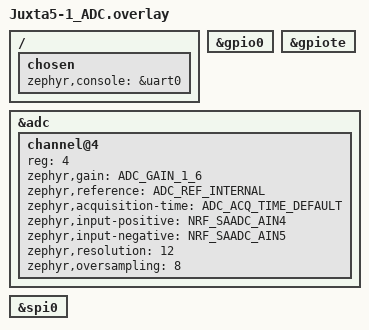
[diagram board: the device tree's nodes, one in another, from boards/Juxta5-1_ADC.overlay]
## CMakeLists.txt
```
#-------------------------------------------------------------------------------
# Zephyr Example Application
#
# Copyright (c) 2021 Nordic Semiconductor ASA
# SPDX-License-Identifier: Apache-2.0

cmake_minimum_required(VERSION 3.13.1)
find_package(Zephyr REQUIRED HINTS $ENV{ZEPHYR_BASE})

project(app LANGUAGES C)

target_sources(app PRIVATE 
    src/simple_main.c
    src/juxta5_example.c
)
```

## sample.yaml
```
# This file is provided so that the application can be compiled using Twister,
# the Zephyr testing tool. In this file, multiple combinations can be specified,
# so that you can easily test all of them locally or in CI.
sample:
  description: Example application
  name: example-application
common:
  sysbuild: true
  build_only: true
  integration_platforms:
    - custom_plank
    - Juxta5-1_ADC
tests:
  app.default: {}
  app.debug:
    extra_overlay_confs:
      - debug.conf
```

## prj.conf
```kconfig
# Copyright (c) 2021 Nordic Semiconductor ASA
# SPDX-License-Identifier: Apache-2.0
#
# This file contains selected Kconfig options for the application.

# Enable GPIO for magnet sensor interrupt
CONFIG_GPIO=y

# Enable SPI for FRAM
CONFIG_SPI=y
CONFIG_SPI_NRFX=y

# Enable ADC for differential measurement
CONFIG_ADC=y
CONFIG_ADC_NRFX_SAADC=y

# Enable EEPROM support for FRAM (use standard driver)
CONFIG_EEPROM=y
CONFIG_EEPROM_AT25=y

# Enable logging
CONFIG_LOG=y
CONFIG_LOG_DEFAULT_LEVEL=3

# Enable RTT for logging (since no UART available)
CONFIG_USE_SEGGER_RTT=y
CONFIG_CONSOLE=y
CONFIG_RTT_CONSOLE=y
CONFIG_SEGGER_RTT_MODE_NO_BLOCK_SKIP=y
# Disable UART console (since no UART available)
CONFIG_UART_CONSOLE=n

# Original example application drivers (for custom drivers in common/)
# CONFIG_SENSOR=y  # Disabled for board-specific testing
```

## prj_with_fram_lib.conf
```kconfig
# Copyright (c) 2021 Nordic Semiconductor ASA
# SPDX-License-Identifier: Apache-2.0
#
# Configuration file demonstrating FRAM library usage

# Enable GPIO for magnet sensor interrupt
CONFIG_GPIO=y

# Enable SPI for FRAM
CONFIG_SPI=y
CONFIG_SPI_NRFX=y

# Enable ADC for differential measurement
CONFIG_ADC=y
CONFIG_ADC_NRFX_SAADC=y

# Enable JUXTA FRAM Library (NEW!)
CONFIG_JUXTA_FRAM=y
CONFIG_JUXTA_FRAM_LOG_LEVEL_DBG=y

# Enable logging
CONFIG_LOG=y
CONFIG_LOG_DEFAULT_LEVEL=3

# Enable RTT for logging (since no UART available)
CONFIG_USE_SEGGER_RTT=y
CONFIG_CONSOLE=y
CONFIG_RTT_CONSOLE=y
CONFIG_SEGGER_RTT_MODE_NO_BLOCK_SKIP=y
# Disable UART console (since no UART available)
CONFIG_UART_CONSOLE=n

# Note: EEPROM drivers not needed when using FRAM library
# The library handles SPI communication directly
# CONFIG_EEPROM=y
# CONFIG_EEPROM_AT25=y 
```

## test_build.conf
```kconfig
# Minimal test configuration for Juxta5-1_ADC
# This removes potentially problematic drivers

# Basic system
CONFIG_GPIO=y
CONFIG_LOG=y
CONFIG_LOG_DEFAULT_LEVEL=3

# Enable RTT for logging (since no UART available)
CONFIG_USE_SEGGER_RTT=y
CONFIG_RTT_CONSOLE=y

# SPI for FRAM
CONFIG_SPI=y
CONFIG_SPI_NRFX=y

# ADC for differential measurement
CONFIG_ADC=y
CONFIG_ADC_NRFX_SAADC=y

# EEPROM for FRAM
CONFIG_EEPROM=y
CONFIG_EEPROM_AT25=y 
```

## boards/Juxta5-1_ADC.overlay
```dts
/*
 * Board overlay for Juxta5-1_ADC specific configurations
 * This file demonstrates how to use all the board peripherals
 */

/ {
	chosen {
		/* No UART available on this board */
		zephyr,console = &uart0; /* Will be ignored since no UART */
	};
};

/* Configure GPIO for magnet sensor interrupt */
&gpio0 {
	status = "okay";
};

/* Configure GPIOTE for interrupt handling */
&gpiote {
	status = "okay";
};

/* Configure ADC for differential measurement */
&adc {
	status = "okay";
	
	/* ADC channel 4 configured for differential measurement */
	/* P0.04 (negative) and P0.05 (positive) */
	#address-cells = <1>;
	#size-cells = <0>;
	
	channel@4 {
		reg = <4>;
		zephyr,gain = "ADC_GAIN_1_6";
		zephyr,reference = "ADC_REF_INTERNAL";
		zephyr,acquisition-time = <ADC_ACQ_TIME_DEFAULT>;
		zephyr,input-positive = <NRF_SAADC_AIN4>; /* P0.04 */
		zephyr,input-negative = <NRF_SAADC_AIN5>; /* P0.05 */
		zephyr,resolution = <12>;
		zephyr,oversampling = <8>;
	};
};

/* Configure SPI for FRAM */
&spi0 {
	status = "okay";
	
	/* FRAM device is already configured in board DTS */
	/* Access via device tree alias: spi-fram */
}; 
```

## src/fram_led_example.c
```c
/*
 * Example demonstrating shared CS/LED pin usage
 * Shows how to safely switch between FRAM and LED modes
 */

#include <zephyr/kernel.h>
#include <zephyr/device.h>
#include <zephyr/drivers/gpio.h>
#include <zephyr/logging/log.h>
#include <juxta_fram/fram.h>
#include <string.h>

LOG_MODULE_REGISTER(fram_led_example, LOG_LEVEL_DBG);

/* Device tree definitions */
#define LED_NODE DT_ALIAS(led0)
#define FRAM_NODE DT_ALIAS(spi_fram)

/* GPIO specifications */
static const struct gpio_dt_spec led_gpio = GPIO_DT_SPEC_GET(LED_NODE, gpios);

/* FRAM device instance */
static struct juxta_fram_device fram_dev;

/**
 * @brief Demonstrate FRAM operations
 */
static int demo_fram_operations(void)
{
    int ret;

    LOG_INF("=== FRAM Operations Demo ===");

    /* FRAM operations automatically switch to SPI mode */
    uint8_t test_data[] = {0x11, 0x22, 0x33, 0x44};
    uint32_t test_addr = 0x2000;

    ret = juxta_fram_write(&fram_dev, test_addr, test_data, sizeof(test_data));
    if (ret < 0)
    {
        LOG_ERR("FRAM write failed: %d", ret);
        return ret;
    }

    uint8_t read_data[sizeof(test_data)] = {0};
    ret = juxta_fram_read(&fram_dev, test_addr, read_data, sizeof(read_data));
    if (ret < 0)
    {
        LOG_ERR("FRAM read failed: %d", ret);
        return ret;
    }

    /* Verify data */
    bool match = true;
    for (size_t i = 0; i < sizeof(test_data); i++)
    {
        if (test_data[i] != read_data[i])
        {
            match = false;
            break;
        }
    }

    if (match)
    {
        LOG_INF("✅ FRAM read/write successful");
    }
    else
    {
        LOG_ERR("❌ FRAM data mismatch");
        return -1;
    }

    return 0;
}

/**
 * @brief Demonstrate LED operations
 */
static int demo_led_operations(void)
{
    int ret;

    LOG_INF("=== LED Operations Demo ===");

    /* Switch to LED mode */
    ret = juxta_fram_led_mode_enable(&fram_dev);
    if (ret < 0)
    {
        LOG_ERR("Failed to enable LED mode: %d", ret);
        return ret;
    }

    LOG_INF("LED mode enabled - testing LED functions...");

    /* Test individual LED functions */
    LOG_INF("Turning LED ON");
    ret = juxta_fram_led_on(&fram_dev);
    if (ret < 0)
    {
        LOG_ERR("LED on failed: %d", ret);
        return ret;
    }
    k_sleep(K_MSEC(500));

    LOG_INF("Turning LED OFF");
    ret = juxta_fram_led_off(&fram_dev);
    if (ret < 0)
    {
        LOG_ERR("LED off failed: %d", ret);
        return ret;
    }
    k_sleep(K_MSEC(500));

    /* Test toggle function */
    LOG_INF("Toggling LED 5 times...");
    for (int i = 0; i < 5; i++)
    {
        ret = juxta_fram_led_toggle(&fram_dev);
        if (ret < 0)
        {
            LOG_ERR("LED toggle failed: %d", ret);
            return ret;
        }
        k_sleep(K_MSEC(200));
    }

    /* Test set function */
    LOG_INF("Using led_set function...");
    ret = juxta_fram_led_set(&fram_dev, true); /* ON */
    if (ret < 0)
    {
        LOG_ERR("LED set failed: %d", ret);
        return ret;
    }
    k_sleep(K_MSEC(300));

    ret = juxta_fram_led_set(&fram_dev, false); /* OFF */
    if (ret < 0)
    {
        LOG_ERR("LED set failed: %d", ret);
        return ret;
    }

    LOG_INF("✅ LED operations successful");
    return 0;
}

/**
 * @brief Demonstrate mixed FRAM and LED usage
 */
static int demo_mixed_operations(void)
{
    int ret;

    LOG_INF("=== Mixed FRAM/LED Operations Demo ===");

    for (int cycle = 0; cycle < 3; cycle++)
    {
        LOG_INF("--- Cycle %d ---", cycle + 1);

        /* Store cycle count in FRAM */
        uint32_t cycle_addr = 0x3000 + (cycle * 4);
        ret = juxta_fram_write(&fram_dev, cycle_addr, (uint8_t *)&cycle, sizeof(cycle));
        if (ret < 0)
        {
            LOG_ERR("Failed to write cycle to FRAM: %d", ret);
            return ret;
        }
        LOG_INF("Stored cycle %d in FRAM at address 0x%06X", cycle, cycle_addr);

        /* Switch to LED mode and blink */
        ret = juxta_fram_led_mode_enable(&fram_dev);
        if (ret < 0)
        {
            LOG_ERR("Failed to enable LED mode: %d", ret);
            return ret;
        }

        /* Blink LED (cycle + 1) times */
        LOG_INF("Blinking LED %d times", cycle + 1);
        for (int blink = 0; blink < (cycle + 1); blink++)
        {
            juxta_fram_led_on(&fram_dev);
            k_sleep(K_MSEC(200));
            juxta_fram_led_off(&fram_dev);
            k_sleep(K_MSEC(200));
        }

        /* Read back from FRAM (automatically switches to SPI mode) */
        int read_cycle = -1;
        ret = juxta_fram_read(&fram_dev, cycle_addr, (uint8_t *)&read_cycle, sizeof(read_cycle));
        if (ret < 0)
        {
            LOG_ERR("Failed to read cycle from FRAM: %d", ret);
            return ret;
        }

        if (read_cycle == cycle)
        {
            LOG_INF("✅ Cycle %d verified from FRAM", read_cycle);
        }
        else
        {
            LOG_ERR("❌ FRAM verification failed: expected %d, got %d", cycle, read_cycle);
            return -1;
        }

        k_sleep(K_SECONDS(1));
    }

    LOG_INF("✅ Mixed operations successful");
    return 0;
}

/**
 * @brief Demonstrate error handling when using wrong mode
 */
static int demo_error_handling(void)
{
    int ret;

    LOG_INF("=== Error Handling Demo ===");

    /* Try LED operation without enabling LED mode */
    LOG_INF("Attempting LED operation in SPI mode (should fail)...");
    ret = juxta_fram_led_on(&fram_dev);
    if (ret == JUXTA_FRAM_ERROR_MODE)
    {
        LOG_INF("✅ Correctly rejected LED operation in SPI mode");
    }
    else
    {
        LOG_ERR("❌ Should have failed with mode error");
        return -1;
    }

    /* Enable LED mode */
    ret = juxta_fram_led_mode_enable(&fram_dev);
    if (ret < 0)
    {
        LOG_ERR("Failed to enable LED mode: %d", ret);
        return ret;
    }

    /* Now LED operations should work */
    ret = juxta_fram_led_on(&fram_dev);
    if (ret == JUXTA_FRAM_OK)
    {
        LOG_INF("✅ LED operation successful after enabling LED mode");
    }
    else
    {
        LOG_ERR("❌ LED operation failed: %d", ret);
        return ret;
    }

    /* FRAM operation will automatically switch modes */
    LOG_INF("Performing FRAM operation (should auto-switch modes)...");
    uint8_t test_byte = 0x55;
    ret = juxta_fram_write_byte(&fram_dev, 0x4000, test_byte);
    if (ret == JUXTA_FRAM_OK)
    {
        LOG_INF("✅ FRAM operation successful (auto mode switch)");
    }
    else
    {
        LOG_ERR("❌ FRAM operation failed: %d", ret);
        return ret;
    }

    /* Check current mode */
    if (juxta_fram_is_led_mode(&fram_dev))
    {
        LOG_INF("Currently in LED mode");
    }
    else
    {
        LOG_INF("Currently in SPI mode");
    }

    LOG_INF("✅ Error handling demo successful");
    return 0;
}

/**
 * @brief Main demonstration function
 */
int fram_led_example_main(void)
{
    int ret;

    LOG_INF("Starting FRAM/LED Shared Pin Demo");

    /* Initialize FRAM */
    ret = juxta_fram_init_dt(&fram_dev, DEVICE_DT_GET(FRAM_NODE), &led_gpio);
    if (ret < 0)
    {
        LOG_ERR("Failed to initialize FRAM: %d", ret);
        return ret;
    }

    /* Verify FRAM is working */
    ret = juxta_fram_test(&fram_dev, 0x1000);
    if (ret < 0)
    {
        LOG_ERR("FRAM test failed: %d", ret);
        return ret;
    }

    LOG_INF("🎯 FRAM Library initialized successfully");
    LOG_INF("Pin P0.%02d is shared between FRAM CS and LED", led_gpio.pin);

    /* Run demonstration functions */
    ret = demo_fram_operations();
    if (ret < 0)
        return ret;

    k_sleep(K_SECONDS(1));

    ret = demo_led_operations();
    if (ret < 0)
        return ret;

    k_sleep(K_SECONDS(1));

    ret = demo_mixed_operations();
    if (ret < 0)
        return ret;

    k_sleep(K_SECONDS(1));

    ret = demo_error_handling();
    if (ret < 0)
        return ret;

    LOG_INF("🎉 All demonstrations completed successfully!");

    /* Final demonstration: continuous operation */
    LOG_INF("Starting continuous demo (Ctrl+C to stop)...");

    uint32_t counter = 0;
    while (1)
    {
        /* Store counter in FRAM */
        uint32_t addr = 0x5000;
        ret = juxta_fram_write(&fram_dev, addr, (uint8_t *)&counter, sizeof(counter));
        if (ret < 0)
        {
            LOG_ERR("FRAM write failed: %d", ret);
            break;
        }

        /* Switch to LED mode and flash */
        juxta_fram_led_mode_enable(&fram_dev);
        juxta_fram_led_on(&fram_dev);
        k_sleep(K_MSEC(100));
        juxta_fram_led_off(&fram_dev);

        /* Read back from FRAM */
        uint32_t read_counter;
        ret = juxta_fram_read(&fram_dev, addr, (uint8_t *)&read_counter, sizeof(read_counter));
        if (ret < 0)
        {
            LOG_ERR("FRAM read failed: %d", ret);
            break;
        }

        LOG_INF("Counter: %u (FRAM verified)", read_counter);

        counter++;
        k_sleep(K_SECONDS(2));
    }

    return 0;
}
```

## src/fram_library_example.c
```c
/*
 * Example usage of the JUXTA FRAM Library
 * This demonstrates the clean API for FRAM operations
 */

#include <zephyr/kernel.h>
#include <zephyr/device.h>
#include <zephyr/drivers/gpio.h>
#include <zephyr/logging/log.h>
#include <juxta_fram/fram.h>
#include <string.h>

LOG_MODULE_REGISTER(fram_example, LOG_LEVEL_DBG);

/* Device tree definitions */
#define LED_NODE DT_ALIAS(led0)
#define FRAM_NODE DT_ALIAS(spi_fram)

/* GPIO specifications */
static const struct gpio_dt_spec led = GPIO_DT_SPEC_GET(LED_NODE, gpios);

/* FRAM device instance */
static struct juxta_fram_device fram_dev;

/**
 * @brief Example of FRAM library usage
 */
int fram_library_example_main(void)
{
    int ret;

    LOG_INF("Starting FRAM Library Example");

    /* Initialize FRAM using the library */
    ret = juxta_fram_init_dt(&fram_dev, DEVICE_DT_GET(FRAM_NODE), &led);
    if (ret < 0)
    {
        LOG_ERR("Failed to initialize FRAM: %d", ret);
        return ret;
    }

    /* Verify FRAM device ID */
    struct juxta_fram_id id;
    ret = juxta_fram_read_id(&fram_dev, &id);
    if (ret < 0)
    {
        LOG_ERR("Failed to verify FRAM ID: %d", ret);
        return ret;
    }

    LOG_INF("FRAM Device ID verified:");
    LOG_INF("  Manufacturer: 0x%02X", id.manufacturer_id);
    LOG_INF("  Continuation: 0x%02X", id.continuation_code);
    LOG_INF("  Product ID 1: 0x%02X", id.product_id_1);
    LOG_INF("  Product ID 2: 0x%02X", id.product_id_2);

    /* Run built-in test */
    ret = juxta_fram_test(&fram_dev, 0x1000); /* Test at address 0x1000 */
    if (ret < 0)
    {
        LOG_ERR("FRAM test failed: %d", ret);
        return ret;
    }

    /* Example: Write a string to FRAM */
    const char *test_string = "Hello FRAM Library!";
    uint32_t string_addr = 0x2000;

    ret = juxta_fram_write(&fram_dev, string_addr,
                           (const uint8_t *)test_string,
                           strlen(test_string) + 1); /* +1 for null terminator */
    if (ret < 0)
    {
        LOG_ERR("Failed to write string to FRAM: %d", ret);
        return ret;
    }

    LOG_INF("Wrote string to FRAM at address 0x%06X", string_addr);

    /* Example: Read the string back */
    char read_buffer[64] = {0};
    ret = juxta_fram_read(&fram_dev, string_addr,
                          (uint8_t *)read_buffer,
                          strlen(test_string) + 1);
    if (ret < 0)
    {
        LOG_ERR("Failed to read string from FRAM: %d", ret);
        return ret;
    }

    LOG_INF("Read string from FRAM: '%s'", read_buffer);

    /* Verify the data matches */
    if (strcmp(test_string, read_buffer) == 0)
    {
        LOG_INF("✅ String read/write test passed!");
    }
    else
    {
        LOG_ERR("❌ String read/write test failed!");
        return -1;
    }

    /* Example: Write and read individual bytes */
    uint32_t data_addr = 0x3000;
    uint8_t test_data[] = {0xAA, 0x55, 0xFF, 0x00, 0x12, 0x34, 0x56, 0x78};
    uint8_t read_data[sizeof(test_data)] = {0};

    ret = juxta_fram_write(&fram_dev, data_addr, test_data, sizeof(test_data));
    if (ret < 0)
    {
        LOG_ERR("Failed to write test data: %d", ret);
        return ret;
    }

    ret = juxta_fram_read(&fram_dev, data_addr, read_data, sizeof(read_data));
    if (ret < 0)
    {
        LOG_ERR("Failed to read test data: %d", ret);
        return ret;
    }

    /* Verify byte data */
    bool data_match = true;
    for (size_t i = 0; i < sizeof(test_data); i++)
    {
        if (test_data[i] != read_data[i])
        {
            LOG_ERR("Data mismatch at index %zu: wrote 0x%02X, read 0x%02X",
                    i, test_data[i], read_data[i]);
            data_match = false;
        }
    }

    if (data_match)
    {
        LOG_INF("✅ Byte array read/write test passed!");
    }
    else
    {
        LOG_ERR("❌ Byte array read/write test failed!");
        return -1;
    }

    /* Example: Use convenience functions for single bytes */
    uint32_t byte_addr = 0x4000;
    uint8_t write_byte = 0xA5;
    uint8_t read_byte;

    ret = juxta_fram_write_byte(&fram_dev, byte_addr, write_byte);
    if (ret < 0)
    {
        LOG_ERR("Failed to write single byte: %d", ret);
        return ret;
    }

    ret = juxta_fram_read_byte(&fram_dev, byte_addr, &read_byte);
    if (ret < 0)
    {
        LOG_ERR("Failed to read single byte: %d", ret);
        return ret;
    }

    if (write_byte == read_byte)
    {
        LOG_INF("✅ Single byte read/write test passed! (0x%02X)", read_byte);
    }
    else
    {
        LOG_ERR("❌ Single byte test failed: wrote 0x%02X, read 0x%02X",
                write_byte, read_byte);
        return -1;
    }

    LOG_INF("🎉 All FRAM library tests completed successfully!");

    /* Main loop - demonstrate periodic FRAM operations */
    uint32_t counter = 0;
    uint32_t counter_addr = 0x5000;

    while (1)
    {
        /* Write counter value to FRAM */
        ret = juxta_fram_write(&fram_dev, counter_addr,
                               (uint8_t *)&counter, sizeof(counter));
        if (ret < 0)
        {
            LOG_ERR("Failed to write counter: %d", ret);
        }
        else
        {
            LOG_INF("Stored counter value %u to FRAM", counter);
        }

        counter++;
        k_sleep(K_SECONDS(5));

        /* Every 10 iterations, read back and verify */
        if ((counter % 10) == 0)
        {
            uint32_t read_counter;
            ret = juxta_fram_read(&fram_dev, counter_addr,
                                  (uint8_t *)&read_counter, sizeof(read_counter));
            if (ret < 0)
            {
                LOG_ERR("Failed to read counter: %d", ret);
            }
            else
            {
                LOG_INF("Read counter from FRAM: %u", read_counter);
                if (read_counter == (counter - 1))
                {
                    LOG_INF("✅ Counter verification passed");
                }
                else
                {
                    LOG_ERR("❌ Counter verification failed");
                }
            }
        }
    }

    return 0;
}
```

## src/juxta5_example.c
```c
/*
 * Example code for Juxta5-1 board peripherals
 * This demonstrates how to use SPI FRAM, ADC, GPIO interrupt, and shared LED/CS
 * with low-power sleep until magnet sensor interrupt
 */

#include <zephyr/kernel.h>
#include <zephyr/device.h>
#include <zephyr/drivers/gpio.h>
#include <zephyr/drivers/spi.h>
#include <zephyr/drivers/adc.h>
#include <zephyr/drivers/eeprom.h>
#include <zephyr/logging/log.h>
#include <zephyr/pm/pm.h>
#include <string.h>

LOG_MODULE_REGISTER(juxta5_example, LOG_LEVEL_DBG);

/* Device tree definitions */
#define MAGNET_SENSOR_NODE DT_ALIAS(magnet_sensor)
#define LED_NODE DT_ALIAS(led0)
#define FRAM_NODE DT_ALIAS(spi_fram)

/* GPIO specifications */
static const struct gpio_dt_spec magnet_sensor = GPIO_DT_SPEC_GET(MAGNET_SENSOR_NODE, gpios);
static const struct gpio_dt_spec led = GPIO_DT_SPEC_GET(LED_NODE, gpios);

/* Callback data */
static struct gpio_callback magnet_cb_data;

/* Semaphore for signaling magnet sensor interrupt */
static K_SEM_DEFINE(magnet_sem, 0, 1);

/* Counter for magnet sensor events */
static uint32_t magnet_event_count = 0;

/* ADC configuration */
#define ADC_NODE DT_NODELABEL(adc)
#define ADC_CHANNEL_ID 4
#define ADC_CHANNEL_INPUT ADC_CHANNEL_ID

static const struct device *adc_dev;
static const struct adc_channel_cfg adc_channel_cfg = {
    .gain = ADC_GAIN_1_6,
    .reference = ADC_REF_INTERNAL,
    .acquisition_time = ADC_ACQ_TIME_DEFAULT,
    .channel_id = ADC_CHANNEL_ID,
    .differential = 1,
    .input_positive = 4, /* P0.04 - AIN4 */
    .input_negative = 5, /* P0.05 - AIN5 */
};

/**
 * @brief Magnet sensor interrupt callback
 */
void magnet_sensor_callback(const struct device *dev, struct gpio_callback *cb, uint32_t pins)
{
    magnet_event_count++;

    LOG_INF("🧲 Magnet sensor interrupt triggered! (Event #%u)", magnet_event_count);

    /* Signal the main thread that an interrupt occurred */
    k_sem_give(&magnet_sem);

    /* Note: P0.20 is shared between LED and FRAM CS */
    /* When using SPI, LED will be controlled by SPI CS */
    /* When using LED, you need to manage this carefully */
}

/**
 * @brief Initialize magnet sensor interrupt
 */
static int init_magnet_sensor(void)
{
    int ret;

    if (!gpio_is_ready_dt(&magnet_sensor))
    {
        LOG_ERR("Magnet sensor GPIO not ready");
        return -ENODEV;
    }

    ret = gpio_pin_configure_dt(&magnet_sensor, GPIO_INPUT);
    if (ret < 0)
    {
        LOG_ERR("Failed to configure magnet sensor pin: %d", ret);
        return ret;
    }

    ret = gpio_pin_interrupt_configure_dt(&magnet_sensor, GPIO_INT_EDGE_TO_ACTIVE);
    if (ret < 0)
    {
        LOG_ERR("Failed to configure magnet sensor interrupt: %d", ret);
        return ret;
    }

    gpio_init_callback(&magnet_cb_data, magnet_sensor_callback, BIT(magnet_sensor.pin));
    gpio_add_callback(magnet_sensor.port, &magnet_cb_data);

    LOG_INF("Magnet sensor initialized on pin %d (interrupt on rising edge)", magnet_sensor.pin);
    return 0;
}

/**
 * @brief Initialize LED (shared with FRAM CS)
 */
static int init_led(void)
{
    int ret;

    if (!gpio_is_ready_dt(&led))
    {
        LOG_ERR("LED GPIO not ready");
        return -ENODEV;
    }

    ret = gpio_pin_configure_dt(&led, GPIO_OUTPUT_INACTIVE);
    if (ret < 0)
    {
        LOG_ERR("Failed to configure LED pin: %d", ret);
        return ret;
    }

    LOG_INF("LED initialized on pin %d (shared with FRAM CS)", led.pin);
    return 0;
}

/**
 * @brief Initialize ADC for differential measurement
 */
static int init_adc(void)
{
    int ret;

    adc_dev = DEVICE_DT_GET(ADC_NODE);
    if (!device_is_ready(adc_dev))
    {
        LOG_ERR("ADC device not ready");
        return -ENODEV;
    }

    ret = adc_channel_setup(adc_dev, &adc_channel_cfg);
    if (ret < 0)
    {
        LOG_ERR("Failed to setup ADC channel: %d", ret);
        return ret;
    }

    LOG_INF("ADC initialized for differential measurement (P0.04/P0.05)");
    return 0;
}

/**
 * @brief Read differential ADC value
 */
static int read_adc(void)
{
    int ret;
    int16_t buf;

    const struct adc_sequence sequence = {
        .channels = BIT(ADC_CHANNEL_ID),
        .buffer = &buf,
        .buffer_size = sizeof(buf),
        .resolution = 12,
        .oversampling = 8,
        .calibrate = true,
    };

    ret = adc_read(adc_dev, &sequence);
    if (ret < 0)
    {
        LOG_ERR("ADC read failed: %d", ret);
        return ret;
    }

    /* Convert to millivolts */
    int32_t val_mv = buf;
    ret = adc_raw_to_millivolts(adc_ref_internal(adc_dev), ADC_GAIN_1_6, 12, &val_mv);
    if (ret < 0)
    {
        LOG_ERR("ADC conversion failed: %d", ret);
        return ret;
    }

    LOG_INF("ADC differential reading: %d mV (raw: %d)", val_mv, buf);
    return 0;
}

/**
 * @brief Test FRAM memory (when LED is not being used)
 */
static int test_fram(void)
{
    int ret;

    LOG_INF("Testing FRAM (MB85RS1MTPW-G-APEWE1)...");

    /* Get SPI device and configure */
    const struct device *spi_dev = DEVICE_DT_GET(DT_BUS(FRAM_NODE));
    if (!device_is_ready(spi_dev))
    {
        LOG_ERR("SPI bus not ready");
        return -ENODEV;
    }

    struct spi_config spi_cfg = {
        .frequency = 8000000, /* 8MHz - standard SPI clock */
        .operation = SPI_WORD_SET(8) | SPI_TRANSFER_MSB,
        .slave = DT_REG_ADDR(FRAM_NODE),
        .cs = {
            .gpio = {
                .port = led.port,
                .pin = led.pin,
                .dt_flags = led.dt_flags},
            .delay = 0}};

    LOG_INF("Testing FRAM with direct SPI communication...");

    /* Step 1: Write Enable */
    uint8_t tx_wren = 0x06;
    const struct spi_buf tx_buf_wren = {
        .buf = &tx_wren,
        .len = 1};
    const struct spi_buf_set tx_wren_set = {
        .buffers = &tx_buf_wren,
        .count = 1};

    ret = spi_write(spi_dev, &spi_cfg, &tx_wren_set);
    if (ret < 0)
    {
        LOG_ERR("Failed to send WREN command: %d", ret);
        return ret;
    }

    k_usleep(30); /* Consistent delay between transactions */

    /* Step 2: Write Data - store the event count */
    uint8_t tx_write[] = {
        0x02,                                /* Write command */
        0x00, 0x10, 0x00,                    /* 24-bit address (0x001000) */
        (uint8_t)(magnet_event_count & 0xFF) /* Store event count as test data */
    };
    const struct spi_buf tx_buf_write = {
        .buf = tx_write,
        .len = sizeof(tx_write)};
    const struct spi_buf_set tx_write_set = {
        .buffers = &tx_buf_write,
        .count = 1};

    ret = spi_write(spi_dev, &spi_cfg, &tx_write_set);
    if (ret < 0)
    {
        LOG_ERR("Failed to write test byte: %d", ret);
        return ret;
    }

    k_usleep(30); /* Consistent delay between transactions */

    /* Step 3: Read Data */
    uint8_t tx_read[] = {
        0x03,             /* Read command */
        0x00, 0x10, 0x00, /* 24-bit address */
        0x00              /* Dummy byte to receive data */
    };
    uint8_t rx_read[sizeof(tx_read)] = {0};

    const struct spi_buf tx_buf_read = {
        .buf = tx_read,
        .len = sizeof(tx_read)};
    const struct spi_buf rx_buf_read = {
        .buf = rx_read,
        .len = sizeof(rx_read)};
    const struct spi_buf_set tx_read_set = {
        .buffers = &tx_buf_read,
        .count = 1};
    const struct spi_buf_set rx_read_set = {
        .buffers = &rx_buf_read,
        .count = 1};

    ret = spi_transceive(spi_dev, &spi_cfg, &tx_read_set, &rx_read_set);
    if (ret < 0)
    {
        LOG_ERR("Failed to read test byte: %d", ret);
        return ret;
    }

    LOG_INF("Direct SPI test - wrote event count %u, read back 0x%02X",
            magnet_event_count, rx_read[4]);

    k_usleep(30); /* Consistent delay before RDID */

    /* Step 4: Device ID Read (moved to end since it has different length) */
    uint8_t tx_rdid[] = {
        0x9F,                  /* RDID command */
        0x00, 0x00, 0x00, 0x00 /* 32 cycles needed for complete ID */
    };
    uint8_t rx_rdid[5] = {0}; /* 1 byte command + 4 bytes response */

    const struct spi_buf tx_buf = {
        .buf = tx_rdid,
        .len = sizeof(tx_rdid)};
    const struct spi_buf rx_buf = {
        .buf = rx_rdid,
        .len = sizeof(rx_rdid)};
    const struct spi_buf_set tx = {
        .buffers = &tx_buf,
        .count = 1};
    const struct spi_buf_set rx = {
        .buffers = &rx_buf,
        .count = 1};

    ret = spi_transceive(spi_dev, &spi_cfg, &tx, &rx);
    if (ret < 0)
    {
        LOG_ERR("Failed to read device ID: %d", ret);
        return ret;
    }

    LOG_INF("Device ID read:");
    LOG_INF("  Manufacturer ID: 0x%02X (expected: 0x04 Fujitsu)", rx_rdid[1]);
    LOG_INF("  Continuation: 0x%02X (expected: 0x7F)", rx_rdid[2]);
    LOG_INF("  Product ID 1: 0x%02X (expected: 0x27 - 1Mbit)", rx_rdid[3]);
    LOG_INF("  Product ID 2: 0x%02X (expected: 0x03)", rx_rdid[4]);

    return 0;
}

/**
 * @brief Handle wake-up activities after magnet sensor interrupt
 */
static void handle_magnet_event(void)
{
    LOG_INF("🔋 Device woke up from sleep due to magnet sensor!");

    /* Read current ADC value */
    LOG_INF("📊 Reading sensors after wake-up...");
    read_adc();

    /* Store event in FRAM for persistence */
    LOG_INF("💾 Storing event data to FRAM...");
    test_fram();

    /* Optional: Flash LED briefly to indicate wake-up */
    /* Note: Commented out because LED shares pin with FRAM CS */
    /*
    gpio_pin_set_dt(&led, 1);
    k_msleep(100);
    gpio_pin_set_dt(&led, 0);
    */

    LOG_INF("✅ Event processing complete. Returning to sleep...");
}

/**
 * @brief Main application entry point
 */
int juxta5_example_main(void)
{
    int ret;

    LOG_INF("Starting Juxta5-1 Low-Power Magnet Sensor Example");

    /* Initialize peripherals */
    ret = init_magnet_sensor();
    if (ret < 0)
    {
        return ret;
    }

    ret = init_led();
    if (ret < 0)
    {
        return ret;
    }

    ret = init_adc();
    if (ret < 0)
    {
        return ret;
    }

    LOG_INF("All peripherals initialized successfully");
    LOG_INF("🔋 Entering low-power mode - device will sleep until magnet sensor interrupt");
    LOG_INF("🧲 Trigger the magnet sensor (P0.%02d) to wake the device", magnet_sensor.pin);

    /* Main loop - sleep until interrupt */
    while (1)
    {
        /* Wait for magnet sensor interrupt (blocks until interrupt occurs) */
        ret = k_sem_take(&magnet_sem, K_FOREVER);
        if (ret == 0)
        {
            /* Process the magnet sensor event */
            handle_magnet_event();
        }

        /* Brief delay before going back to sleep */
        k_msleep(100);

        LOG_INF("💤 Going back to sleep... (Event count: %u)", magnet_event_count);
    }

    return 0;
}
```

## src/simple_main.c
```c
/*
 * Simple main.c for Juxta5-1_ADC board testing
 * This version only includes the board-specific example without custom drivers
 */

#include <zephyr/kernel.h>
#include <zephyr/logging/log.h>
#include <app_version.h>

LOG_MODULE_REGISTER(main, CONFIG_LOG_DEFAULT_LEVEL);

// Forward declaration for board-specific example
extern int juxta5_example_main(void);

int main(void)
{
    printk("Running Juxta5-1_ADC Board Example %s\n", APP_VERSION_STRING);
    return juxta5_example_main();
} 
```
